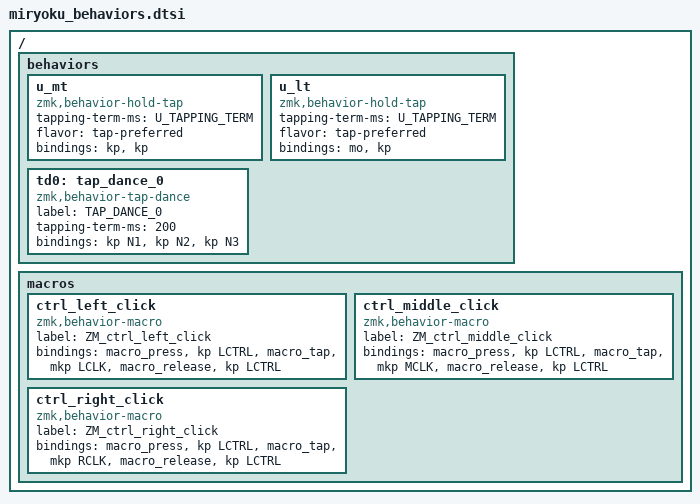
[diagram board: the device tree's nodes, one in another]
// Copyright 2022 Manna Harbour
// https://github.com/manna-harbour/miryoku

/ {
  behaviors {
    u_mt: u_mt {
      compatible = "zmk,behavior-hold-tap";
      #binding-cells = <2>;
      tapping-term-ms = <U_TAPPING_TERM>;
      flavor = "tap-preferred";
      bindings = <&kp>, <&kp>;
    };
    u_lt: u_lt {
      compatible = "zmk,behavior-hold-tap";
      #binding-cells = <2>;
      tapping-term-ms = <U_TAPPING_TERM>;
      flavor = "tap-preferred";
      bindings = <&mo>, <&kp>;
    };
    td0: tap_dance_0 {
      compatible = "zmk,behavior-tap-dance";
      label = "TAP_DANCE_0";
      #binding-cells = <0>;
      tapping-term-ms = <200>;
      bindings = <&kp N1>, <&kp N2>, <&kp N3>;
    };
  };
};

/ {
    macros {
        ctrl_left_click: ctrl_left_click {
            label = "ZM_ctrl_left_click";
            compatible = "zmk,behavior-macro";
            #binding-cells = <0>;
            bindings
                = <&macro_press &kp LCTRL>
                , <&macro_tap &mkp LCLK>
                , <&macro_release &kp LCTRL>
                ;
        };
        ctrl_middle_click: ctrl_middle_click {
            label = "ZM_ctrl_middle_click";
            compatible = "zmk,behavior-macro";
            #binding-cells = <0>;
            bindings
                = <&macro_press &kp LCTRL>
                , <&macro_tap &mkp MCLK>
                , <&macro_release &kp LCTRL>
                ;
        };
        ctrl_right_click: ctrl_right_click {
            label = "ZM_ctrl_right_click";
            compatible = "zmk,behavior-macro";
            #binding-cells = <0>;
            bindings
                = <&macro_press &kp LCTRL>
                , <&macro_tap &mkp RCLK>
                , <&macro_release &kp LCTRL>
                ;
        };
    };
}; 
